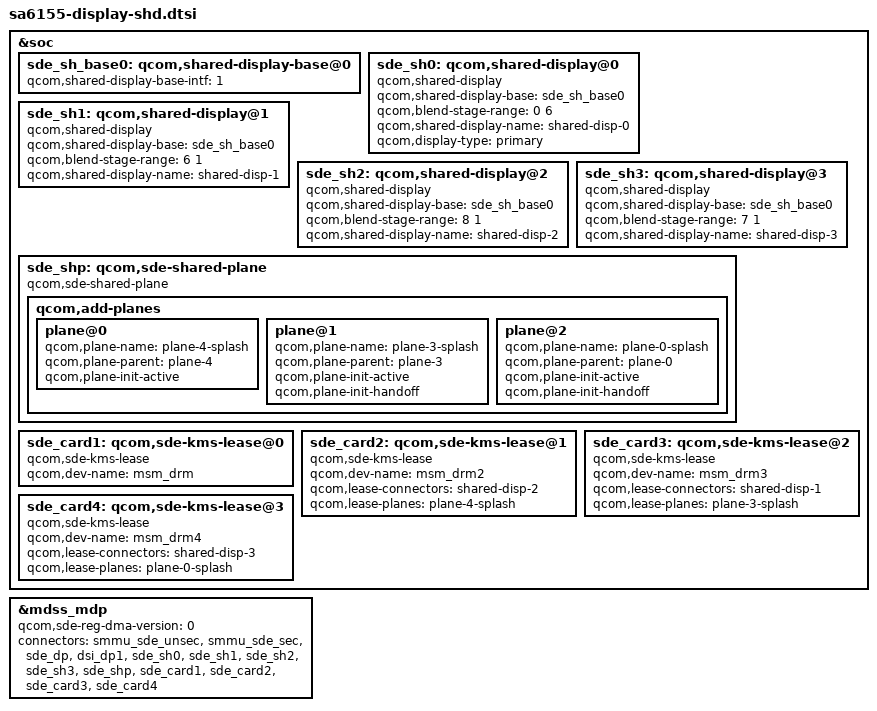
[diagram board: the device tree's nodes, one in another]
&soc {
	sde_sh_base0: qcom,shared-display-base@0 {
		qcom,shared-display-base-intf = <1>;
	};

	sde_sh0: qcom,shared-display@0 {
		compatible = "qcom,shared-display";
		qcom,shared-display-base = <&sde_sh_base0>;
		qcom,blend-stage-range = <0 6>;
		qcom,shared-display-name = "shared-disp-0";
		qcom,display-type = "primary";
	};

	sde_sh1: qcom,shared-display@1 {
		compatible = "qcom,shared-display";
		qcom,shared-display-base = <&sde_sh_base0>;
		qcom,blend-stage-range = <6 1>;
		qcom,shared-display-name = "shared-disp-1";
	};

	sde_sh2: qcom,shared-display@2 {
		compatible = "qcom,shared-display";
		qcom,shared-display-base = <&sde_sh_base0>;
		qcom,blend-stage-range = <8 1>;
		qcom,shared-display-name = "shared-disp-2";
	};

	sde_sh3: qcom,shared-display@3 {
		compatible = "qcom,shared-display";
		qcom,shared-display-base = <&sde_sh_base0>;
		qcom,blend-stage-range = <7 1>;
		qcom,shared-display-name = "shared-disp-3";
	};

	sde_shp: qcom,sde-shared-plane {
		compatible = "qcom,sde-shared-plane";
		qcom,add-planes {
			plane@0 {
				qcom,plane-name = "plane-4-splash";
				qcom,plane-parent = "plane-4";
				qcom,plane-init-active;
			};
			plane@1 {
				qcom,plane-name = "plane-3-splash";
				qcom,plane-parent = "plane-3";
				qcom,plane-init-active;
				qcom,plane-init-handoff;
			};
			plane@2 {
				qcom,plane-name = "plane-0-splash";
				qcom,plane-parent = "plane-0";
				qcom,plane-init-active;
				qcom,plane-init-handoff;
			};
		};
	};

	sde_card1: qcom,sde-kms-lease@0 {
		compatible = "qcom,sde-kms-lease";
		qcom,dev-name = "msm_drm";
	};

	sde_card2: qcom,sde-kms-lease@1 {
		compatible = "qcom,sde-kms-lease";
		qcom,dev-name = "msm_drm2";
		qcom,lease-connectors = "shared-disp-2";
		qcom,lease-planes = "plane-4-splash";
	};

	sde_card3: qcom,sde-kms-lease@2 {
		compatible = "qcom,sde-kms-lease";
		qcom,dev-name = "msm_drm3";
		qcom,lease-connectors = "shared-disp-1";
		qcom,lease-planes = "plane-3-splash";
	};

	sde_card4: qcom,sde-kms-lease@3 {
		compatible = "qcom,sde-kms-lease";
		qcom,dev-name = "msm_drm4";
		qcom,lease-connectors = "shared-disp-3";
		qcom,lease-planes = "plane-0-splash";
	};
};

&mdss_mdp {
	qcom,sde-reg-dma-version = <0>;
	connectors = <&smmu_sde_unsec &smmu_sde_sec &sde_dp &dsi_dp1
			&sde_sh0 &sde_sh1 &sde_sh2 &sde_sh3 &sde_shp
			&sde_card1 &sde_card2 &sde_card3 &sde_card4>;
};
